# MDR1986VK01 register map
File version: 1.0.2
Registers are 32-bit, read-write, no defined reset value unless marked. A register's access mark holds for its fields unless they carry their own. Offsets are from the block's base; [hi:lo] are bit positions; {n}, {i} and the like mark numbered series; 'fields as' and 'values as' point back to an identical list.

## MDR_BKP — MDR_BKP description
Base 0x40001000
{0x0+4i} REG_{i:02} (i=0..59) — REG_{i:02} description
0xF0 KEY — KEY description
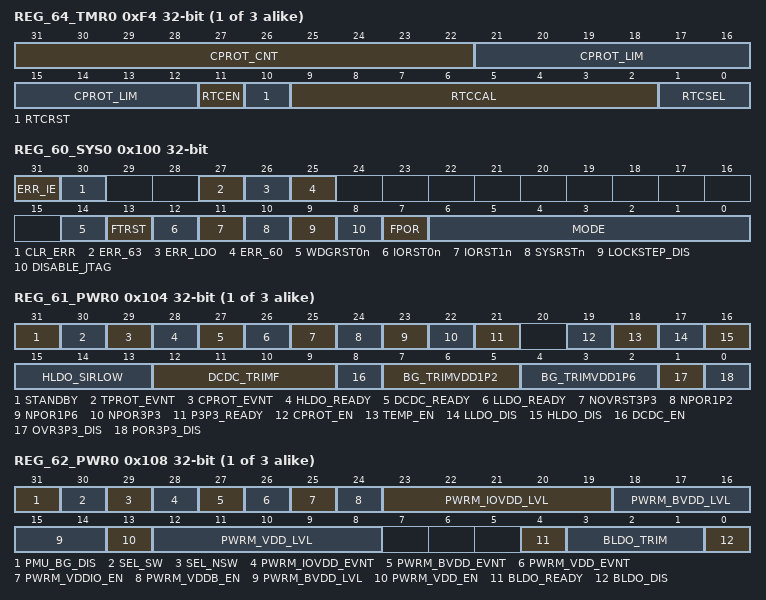
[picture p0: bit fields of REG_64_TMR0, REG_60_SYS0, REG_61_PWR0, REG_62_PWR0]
{0xF4+4i} REG_64_TMR{i} (i=0..2) — REG_64_TMR{i} description
  [31:22] CPROT_CNT — CPROT_CNT description
  [21:12] CPROT_LIM — CPROT_LIM description
  [11] RTCEN — RTCEN description
  [10] RTCRST — RTCRST description
  [9:2] RTCCAL — RTCCAL description
  [1:0] RTCSEL — RTCSEL description
0x100 REG_60_SYS0 — REG_60_SYS0 description
  [31] ERR_IE — ERR_IE description
  [30] CLR_ERR — CLR_ERR description
  [27] ERR_63 — ERR_63 description
  [26] ERR_LDO — ERR_LDO description
  [25] ERR_60 — ERR_60 description
  [14] WDGRST0n — WDGRST0n description
  [13] FTRST — FTRST description
  [12] IORST0n — IORST0n description
  [11] IORST1n — IORST1n description
  [10] SYSRSTn — SYSRSTn description
  [9] LOCKSTEP_DIS — LOCKSTEP_DIS description
  [8] DISABLE_JTAG — DISABLE_JTAG description
  [7] FPOR — FPOR description
  [6:0] MODE — MODE description
{0x104+0x10*i} REG_61_PWR{i} (i=0..2) — REG_61_PWR{i} description
  [31] STANDBY — STANDBY description
  [30] TPROT_EVNT — TPROT_EVNT description
  [29] CPROT_EVNT — CPROT_EVNT description
  [28] HLDO_READY — HLDO_READY description
  [27] DCDC_READY — DCDC_READY description
  [26] LLDO_READY — LLDO_READY description
  [25] NOVRST3P3 — NOVRST3P3 description
  [24] NPOR1P2 — NPOR1P2 description
  [23] NPOR1P6 — NPOR1P6 description
  [22] NPOR3P3 — NPOR3P3 description
  [21] P3P3_READY — P3P3_READY description
  [19] CPROT_EN — CPROT_EN description
  [18] TEMP_EN — TEMP_EN description
  [17] LLDO_DIS — LLDO_DIS description
  [16] HLDO_DIS — HLDO_DIS description
  [15:13] HLDO_SIRLOW — HLDO_SIRLOW description
  [12:9] DCDC_TRIMF — DCDC_TRIMF description
  [8] DCDC_EN — DCDC_EN description
  [7:5] BG_TRIMVDD1P2 — BG_TRIMVDD1P2 description
  [4:2] BG_TRIMVDD1P6 — BG_TRIMVDD1P6 description
  [1] OVR3P3_DIS — OVR3P3_DIS description
  [0] POR3P3_DIS — POR3P3_DIS description
{0x108+0x10*i} REG_62_PWR{i} (i=0..2) — REG_62_PWR{i} description
  [31] PMU_BG_DIS — PMU_BG_DIS description
  [30] SEL_SW — SEL_SW description
  [29] SEL_NSW — SEL_NSW description
  [28] PWRM_IOVDD_EVNT — PWRM_IOVDD_EVNT description
  [27] PWRM_BVDD_EVNT — PWRM_BVDD_EVNT description
  [26] PWRM_VDD_EVNT — PWRM_VDD_EVNT description
  [25] PWRM_VDDIO_EN — PWRM_VDDIO_EN description
  [24] PWRM_VDDB_EN — PWRM_VDDB_EN description
  [23:19] PWRM_IOVDD_LVL — PWRM_IOVDD_LVL description
  [18:14] PWRM_BVDD_LVL — PWRM_BVDD_LVL description
  [13] PWRM_VDD_EN — PWRM_VDD_EN description
  [12:8] PWRM_VDD_LVL — PWRM_VDD_LVL description
  [4] BLDO_READY — BLDO_READY description
  [3:1] BLDO_TRIM — BLDO_TRIM description
  [0] BLDO_DIS — BLDO_DIS description
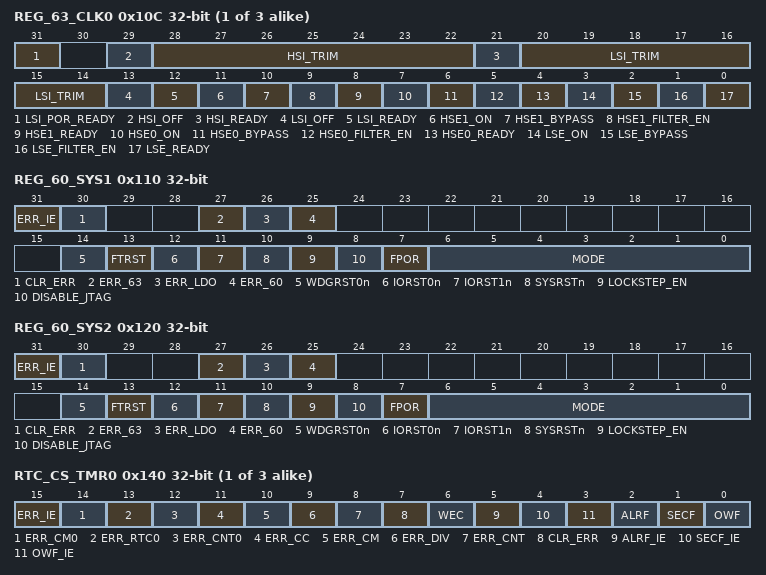
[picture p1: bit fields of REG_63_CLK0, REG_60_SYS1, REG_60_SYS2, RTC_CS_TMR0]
{0x10C+0x10*i} REG_63_CLK{i} (i=0..2) — REG_63_CLK{i} description
  [31] LSI_POR_READY — LSI_POR_READY description
  [29] HSI_OFF — HSI_OFF description
  [28:22] HSI_TRIM — HSI_TRIM description
  [21] HSI_READY — HSI_READY description
  [20:14] LSI_TRIM — LSI_TRIM description
  [13] LSI_OFF — LSI_OFF description
  [12] LSI_READY — LSI_READY description
  [11] HSE1_ON — HSE1_ON description
  [10] HSE1_BYPASS — HSE1_BYPASS description
  [9] HSE1_FILTER_EN — HSE1_FILTER_EN description
  [8] HSE1_READY — HSE1_READY description
  [7] HSE0_ON — HSE0_ON description
  [6] HSE0_BYPASS — HSE0_BYPASS description
  [5] HSE0_FILTER_EN — HSE0_FILTER_EN description
  [4] HSE0_READY — HSE0_READY description
  [3] LSE_ON — LSE_ON description
  [2] LSE_BYPASS — LSE_BYPASS description
  [1] LSE_FILTER_EN — LSE_FILTER_EN description
  [0] LSE_READY — LSE_READY description
0x110 REG_60_SYS1 — REG_60_SYS1 description
  [31] ERR_IE — ERR_IE description
  [30] CLR_ERR — CLR_ERR description
  [27] ERR_63 — ERR_63 description
  [26] ERR_LDO — ERR_LDO description
  [25] ERR_60 — ERR_60 description
  [14] WDGRST0n — WDGRST0n description
  [13] FTRST — FTRST description
  [12] IORST0n — IORST0n description
  [11] IORST1n — IORST1n description
  [10] SYSRSTn — SYSRSTn description
  [9] LOCKSTEP_EN — LOCKSTEP_EN description
  [8] DISABLE_JTAG — DISABLE_JTAG description
  [7] FPOR — FPOR description
  [6:0] MODE — MODE description
0x120 REG_60_SYS2 — REG_60_SYS2 description
  fields as REG_60_SYS1
{0x130+0x20*i} RTC_CNT_TMR{i} (i=0..2) — RTC_CNT_TMR{i} description
{0x134+0x20*i} RTC_DIV_TMR{i} (i=0..2) — RTC_DIV_TMR{i} description
  [19:0] DIV — DIV description
{0x138+0x20*i} RTC_PRL_TMR{i} (i=0..2) — RTC_PRL_TMR{i} description
  [19:0] PRL — PRL description
{0x13C+0x20*i} RTC_ALRM_TMR{i} (i=0..2) — RTC_ALRM_TMR{i} description
{0x140+0x20*i} RTC_CS_TMR{i} (i=0..2) — RTC_CS_TMR{i} description
  [15] ERR_IE — ERR_IE description
  [14] ERR_CM{i} — ERR_CM{i} description
  [13] ERR_RTC{i} — ERR_RTC{i} description
  [12] ERR_CNT{i} — ERR_CNT{i} description
  [11] ERR_CC — ERR_CC description
  [10] ERR_CM — ERR_CM description
  [9] ERR_DIV — ERR_DIV description
  [8] ERR_CNT — ERR_CNT description
  [7] CLR_ERR — CLR_ERR description
  [6] WEC — WEC description
  [5] ALRF_IE — ALRF_IE description
  [4] SECF_IE — SECF_IE description
  [3] OWF_IE — OWF_IE description
  [2] ALRF — ALRF description
  [1] SECF — SECF description
  [0] OWF — OWF description
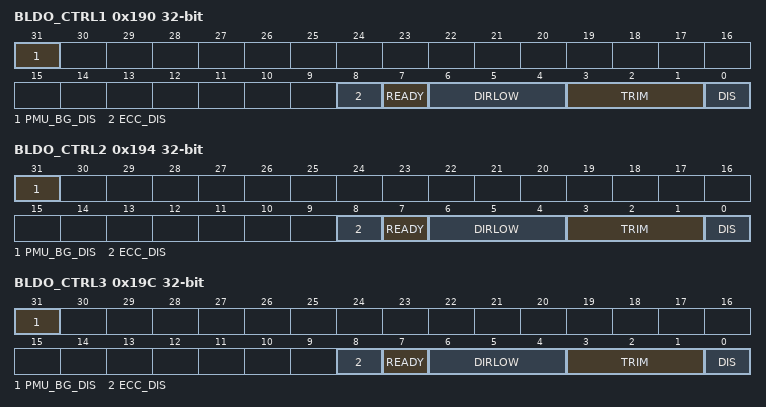
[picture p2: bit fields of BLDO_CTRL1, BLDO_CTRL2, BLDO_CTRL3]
0x190 BLDO_CTRL1 — BLDO_CTRL1 description
  [31] PMU_BG_DIS — PMU_BG_DIS description
  [8] ECC_DIS — ECC_DIS description
  [7] READY — READY description
  [6:4] DIRLOW — DIRLOW description
  [3:1] TRIM — TRIM description
  [0] DIS — DIS description
0x194 BLDO_CTRL2 — BLDO_CTRL2 description
  fields as BLDO_CTRL1
0x19C BLDO_CTRL3 — BLDO_CTRL3 description
  fields as BLDO_CTRL1
